# VPAC0_COMMON_0_IVPAC_TOP_0_CFG_SLV_HTS_S_VBUSP register map
Vendor: Texas Instruments
Registers are 32-bit, read-write, reset 0x0 unless marked. A register's access mark holds for its fields unless they carry their own. Offsets are as the file gives them; [hi:lo] are bit positions; {n}, {i} and the like mark numbered series; 'fields as' and 'values as' point back to an identical list.

## VPAC0_COMMON_0_IVPAC_TOP_0_CFG_SLV_HTS_S_VBUSP (part 2 of 4)
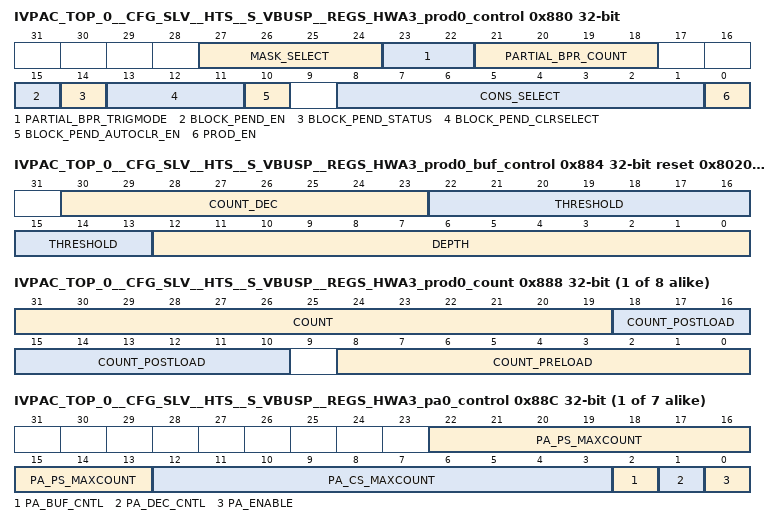
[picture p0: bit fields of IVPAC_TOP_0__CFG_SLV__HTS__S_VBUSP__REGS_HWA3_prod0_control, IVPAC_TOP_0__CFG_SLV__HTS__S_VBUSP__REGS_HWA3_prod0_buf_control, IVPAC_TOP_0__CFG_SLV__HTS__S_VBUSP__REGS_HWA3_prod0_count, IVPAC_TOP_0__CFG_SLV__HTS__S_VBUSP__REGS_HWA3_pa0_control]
0x880 IVPAC_TOP_0__CFG_SLV__HTS__S_VBUSP__REGS_HWA3_prod0_control — Controlling producer socket0 for HWA3
  [27:24] MASK_SELECT — define which tdone_mask apply to prod socket 0. tdone_mask[mask_select] applies to prod_socket0. Valid value in range 0 - 4
  [23:22] PARTIAL_BPR_TRIGMODE — 0: Normal behavior; 1 : Prod Socket 0 is used to trigger DMA channel to transfer end of Row or End of Region Row buffer data for prod socket (0+2)%4. Useful when this Buffer is not completely filled at end of row and it enables triggering separate DMA channel for end of row. Rely on tdone_bpr_early attribute; 2: Prod Socket 0 is used to trigger DMA channel to transfer end of Row or End of Region Row buffer data for prod socket (0+2)%4. Useful when this Buffer is not completely filled at end of row and it enables triggering separate DMA channel for end of row. Rely on end of Row attribute. Must not be used in dual output mode
  [21:18] PARTIAL_BPR_COUNT — Remaining block count to complete configured BPR at End of Row or End of Region Row when LDC is configured in tdone_gen_mode='0'
  [15] BLOCK_PEND_EN — '1' -> block pend at the end of hwa eop enabled at Producer socket 0 , '0' Disable
  [14] BLOCK_PEND_STATUS — '1' -> block pend status at Producer socket 0 , '0' Disable
  [13:11] BLOCK_PEND_CLRSELECT — hts_event_gen[block_pend_clrselect] will be used to clear blocked pend in super pipeline
  [10] BLOCK_PEND_AUTOCLR_EN — '1' -> Enable clearing block pend status at Producer socket 0 by hts_event_gen[block_pend_clrselect], '0' Disable
  [8:1] CONS_SELECT — consumer select for HWA3 prod socket 0. Used in decrementing count of producer buffer
  [0] PROD_EN — '1' -> Producer socket 0 enable , '0' Disable
{0x884+0x20*i} IVPAC_TOP_0__CFG_SLV__HTS__S_VBUSP__REGS_HWA3_prod{i}_buf_control reset 0x802000 (i=0..7) — Controlling producer socket{i} buffer for HWA3
  [30:23] COUNT_DEC — Count decrement value for prod count
  [22:13] THRESHOLD — Count threshold to generate pend for consumer
  [12:0] DEPTH — Maximum number of producer buffer count
{0x888+0x20*i} IVPAC_TOP_0__CFG_SLV__HTS__S_VBUSP__REGS_HWA3_prod{i}_count access per field (i=0..7) — Defining count values for pre/post load for generating pend by HWA3 prod{i}
  [31:19] COUNT ro — current count value
  [18:10] COUNT_POSTLOAD rw — count postload after producer max thread count reached
  [8:0] COUNT_PRELOAD rw — count preload after scheduler start/init
{0x88C+0x20*i} IVPAC_TOP_0__CFG_SLV__HTS__S_VBUSP__REGS_HWA3_pa{i}_control (i=0..6) — control register to manage pattern adapter on HWA3 prod socket{i}
  [22:13] PA_PS_MAXCOUNT — destination count for pattern adaptation (N), M --> N
  [12:3] PA_CS_MAXCOUNT — source count for pattern adaptation (M), M --> N
  [2] PA_BUF_CNTL — '1' -> Apply threshold, count_preload and count_postload on pattern adapter count (use this only when pa_enable='1') '0' -> Apply threshold, count_preload and count_postload on prod count (same behavior as if no pattern adapter. Note when pa_enable='1' and pa_buf_cntl='0' threshold is not used and ignored)
  [1] PA_DEC_CNTL — '1' -> post pattern adaptation, decrement ps count by count_dec , '0' -> post pattern adaptation, decrement ps count by pa_cs_maxcount
  [0] PA_ENABLE — '1' -> pa enable, '0' -> disable
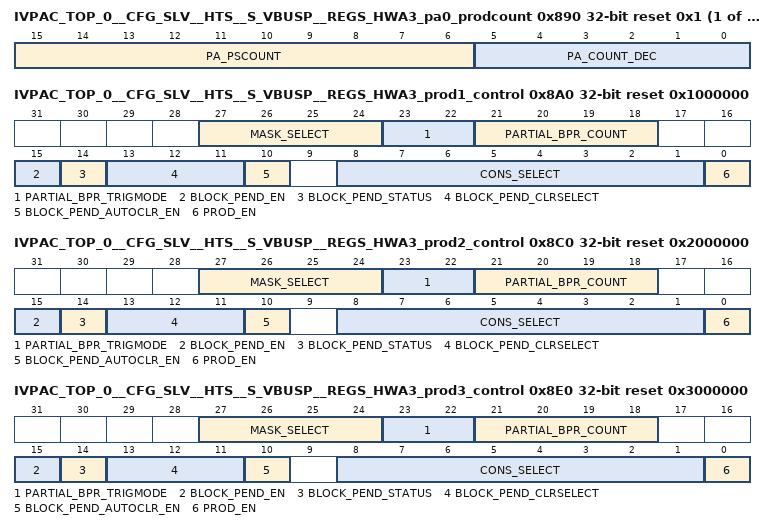
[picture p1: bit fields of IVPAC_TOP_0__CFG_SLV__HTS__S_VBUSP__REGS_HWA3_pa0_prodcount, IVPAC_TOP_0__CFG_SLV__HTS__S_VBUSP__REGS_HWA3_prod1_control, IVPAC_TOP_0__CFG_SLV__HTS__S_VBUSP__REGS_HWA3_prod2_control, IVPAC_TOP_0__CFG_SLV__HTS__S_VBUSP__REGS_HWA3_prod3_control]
{0x890+0x20*i} IVPAC_TOP_0__CFG_SLV__HTS__S_VBUSP__REGS_HWA3_pa{i}_prodcount access per field reset 0x1 (i=0..6) — count values for HWA3 prod socket{i}
  [15:6] PA_PSCOUNT ro — current count value of pa prod count
  [5:0] PA_COUNT_DEC rw — Decrement count value of pa_prod_count after pattern adapter prod count reaches threshold
0x8A0 IVPAC_TOP_0__CFG_SLV__HTS__S_VBUSP__REGS_HWA3_prod1_control reset 0x1000000 — Controlling producer socket1 for HWA3
  [27:24] MASK_SELECT — define which tdone_mask apply to prod socket 1. tdone_mask[mask_select] applies to prod_socket1. Valid value in range 0 - 4
  [23:22] PARTIAL_BPR_TRIGMODE — 0: Normal behavior; 1 : Prod Socket 1 is used to trigger DMA channel to transfer end of Row or End of Region Row buffer data for prod socket (1+2)%4. Useful when this Buffer is not completely filled at end of row and it enables triggering separate DMA channel for end of row. Rely on tdone_bpr_early attribute; 2: Prod Socket 1 is used to trigger DMA channel to transfer end of Row or End of Region Row buffer data for prod socket (1+2)%4. Useful when this Buffer is not completely filled at end of row and it enables triggering separate DMA channel for end of row. Rely on end of Row attribute. Must not be used in dual output mode
  [21:18] PARTIAL_BPR_COUNT — Remaining block count to complete configured BPR at End of Row or End of Region Row when LDC is configured in tdone_gen_mode='0'
  [15] BLOCK_PEND_EN — '1' -> block pend at the end of hwa eop enabled at Producer socket 1 , '0' Disable
  [14] BLOCK_PEND_STATUS — '1' -> block pend status at Producer socket 1 , '0' Disable
  [13:11] BLOCK_PEND_CLRSELECT — hts_event_gen[block_pend_clrselect] will be used to clear blocked pend in super pipeline
  [10] BLOCK_PEND_AUTOCLR_EN — '1' -> Enable clearing block pend status at Producer socket 1 by hts_event_gen[block_pend_clrselect], '0' Disable
  [8:1] CONS_SELECT — consumer select for HWA3 prod socket 1. Used in decrementing count of producer buffer
  [0] PROD_EN — '1' -> Producer socket 1 enable , '0' Disable
0x8C0 IVPAC_TOP_0__CFG_SLV__HTS__S_VBUSP__REGS_HWA3_prod2_control reset 0x2000000 — Controlling producer socket2 for HWA3
  [27:24] MASK_SELECT — define which tdone_mask apply to prod socket 2. tdone_mask[mask_select] applies to prod_socket2. Valid value in range 0 - 4
  [23:22] PARTIAL_BPR_TRIGMODE — 0: Normal behavior; 1 : Prod Socket 2 is used to trigger DMA channel to transfer end of Row or End of Region Row buffer data for prod socket (2+2)%4. Useful when this Buffer is not completely filled at end of row and it enables triggering separate DMA channel for end of row. Rely on tdone_bpr_early attribute; 2: Prod Socket 2 is used to trigger DMA channel to transfer end of Row or End of Region Row buffer data for prod socket (2+2)%4. Useful when this Buffer is not completely filled at end of row and it enables triggering separate DMA channel for end of row. Rely on end of Row attribute. Must not be used in dual output mode
  [21:18] PARTIAL_BPR_COUNT — Remaining block count to complete configured BPR at End of Row or End of Region Row when LDC is configured in tdone_gen_mode='0'
  [15] BLOCK_PEND_EN — '1' -> block pend at the end of hwa eop enabled at Producer socket 2 , '0' Disable
  [14] BLOCK_PEND_STATUS — '1' -> block pend status at Producer socket 2 , '0' Disable
  [13:11] BLOCK_PEND_CLRSELECT — hts_event_gen[block_pend_clrselect] will be used to clear blocked pend in super pipeline
  [10] BLOCK_PEND_AUTOCLR_EN — '1' -> Enable clearing block pend status at Producer socket 2 by hts_event_gen[block_pend_clrselect], '0' Disable
  [8:1] CONS_SELECT — consumer select for HWA3 prod socket 2. Used in decrementing count of producer buffer
  [0] PROD_EN — '1' -> Producer socket 2 enable , '0' Disable
0x8E0 IVPAC_TOP_0__CFG_SLV__HTS__S_VBUSP__REGS_HWA3_prod3_control reset 0x3000000 — Controlling producer socket3 for HWA3
  [27:24] MASK_SELECT — define which tdone_mask apply to prod socket 3. tdone_mask[mask_select] applies to prod_socket3. Valid value in range 0 - 4
  [23:22] PARTIAL_BPR_TRIGMODE — 0: Normal behavior; 1 : Prod Socket 3 is used to trigger DMA channel to transfer end of Row or End of Region Row buffer data for prod socket (3+2)%4. Useful when this Buffer is not completely filled at end of row and it enables triggering separate DMA channel for end of row. Rely on tdone_bpr_early attribute; 2: Prod Socket 3 is used to trigger DMA channel to transfer end of Row or End of Region Row buffer data for prod socket (3+2)%4. Useful when this Buffer is not completely filled at end of row and it enables triggering separate DMA channel for end of row. Rely on end of Row attribute. Must not be used in dual output mode
  [21:18] PARTIAL_BPR_COUNT — Remaining block count to complete configured BPR at End of Row or End of Region Row when LDC is configured in tdone_gen_mode='0'
  [15] BLOCK_PEND_EN — '1' -> block pend at the end of hwa eop enabled at Producer socket 3 , '0' Disable
  [14] BLOCK_PEND_STATUS — '1' -> block pend status at Producer socket 3 , '0' Disable
  [13:11] BLOCK_PEND_CLRSELECT — hts_event_gen[block_pend_clrselect] will be used to clear blocked pend in super pipeline
  [10] BLOCK_PEND_AUTOCLR_EN — '1' -> Enable clearing block pend status at Producer socket 3 by hts_event_gen[block_pend_clrselect], '0' Disable
  [8:1] CONS_SELECT — consumer select for HWA3 prod socket 3. Used in decrementing count of producer buffer
  [0] PROD_EN — '1' -> Producer socket 3 enable , '0' Disable
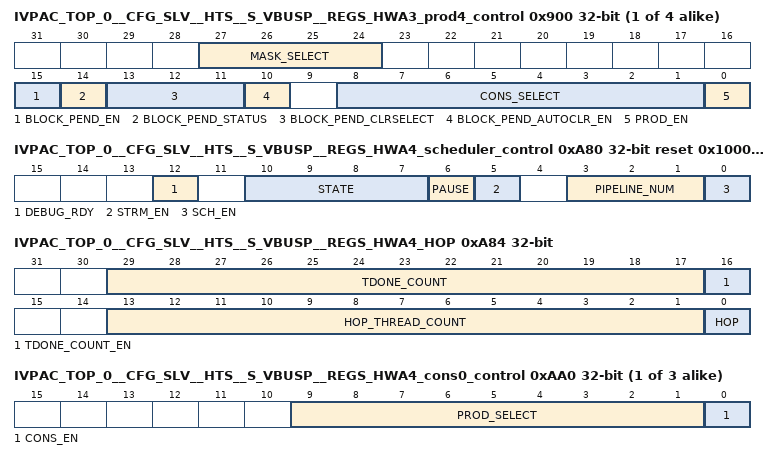
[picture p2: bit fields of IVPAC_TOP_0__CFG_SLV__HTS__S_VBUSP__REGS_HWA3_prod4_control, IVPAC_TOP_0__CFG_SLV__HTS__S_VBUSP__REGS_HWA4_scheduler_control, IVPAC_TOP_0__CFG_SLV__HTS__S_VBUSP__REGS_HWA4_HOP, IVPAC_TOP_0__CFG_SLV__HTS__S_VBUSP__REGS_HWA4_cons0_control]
{0x880+0x20*i} IVPAC_TOP_0__CFG_SLV__HTS__S_VBUSP__REGS_HWA3_prod{i}_control (i=4..7) — Controlling producer socket{i} for HWA3
  [27:24] MASK_SELECT — define which tdone_mask apply to prod socket {i}. tdone_mask[mask_select] applies to prod_socket{i}. Valid value in range 0 - 4
  [15] BLOCK_PEND_EN — '1' -> block pend at the end of hwa eop enabled at Producer socket {i} , '0' Disable
  [14] BLOCK_PEND_STATUS — '1' -> block pend status at Producer socket {i} , '0' Disable
  [13:11] BLOCK_PEND_CLRSELECT — hts_event_gen[block_pend_clrselect] will be used to clear blocked pend in super pipeline
  [10] BLOCK_PEND_AUTOCLR_EN — '1' -> Enable clearing block pend status at Producer socket {i} by hts_event_gen[block_pend_clrselect], '0' Disable
  [8:1] CONS_SELECT — consumer select for HWA3 prod socket {i}. Used in decrementing count of producer buffer
  [0] PROD_EN — '1' -> Producer socket {i} enable , '0' Disable
{0x100+0x260*i} IVPAC_TOP_0__CFG_SLV__HTS__S_VBUSP__REGS_HWA{i}_scheduler_control access per field reset 0x1000 (i=4..8) — Scheduler Control Register
  [12] DEBUG_RDY rw — '0' -> HWA{i} Scheduler resources must not be read during halted state. '1'-> HWA{i} Scheduler resources are readable during halted state
  [10:7] STATE ro — Current state of HWA{i} Scheduler
  [6] PAUSE rw — '1' -> pause/suspend scheduler , '0' -> resume scheduler
  [5] STRM_EN rw — '1' -> Streaming input enable, '0' No streaming input
  [3:1] PIPELINE_NUM rw — Pipeline Number of HWA{i} Scheduler
  [0] SCH_EN rw — scheduler enable; write '1' to enable scheduler
0xA84 IVPAC_TOP_0__CFG_SLV__HTS__S_VBUSP__REGS_HWA4_HOP access per field — Scheduler HOP Control Register. Help in detecting eop within scheduler. Once configured, it counts task/channel starts and stops issuing further starts. Specifically useful for Head of pipe dma scheduler .
  [29:17] TDONE_COUNT ro — current tdone count value
  [16] TDONE_COUNT_EN rw — '1' -> Count tdone(Not impacted due to individual channel mask). Current tdone count available as read value. when enabled, it triggers tdone_intr when (tdone_count==hop_thread_count) , '0' -> No count
  [13:1] HOP_THREAD_COUNT rw — Number of Task count for Head of pipe
  [0] HOP rw — '1' -> Head of Pipe producer Sch , '0' -> No hop
{0xAA0+8i} IVPAC_TOP_0__CFG_SLV__HTS__S_VBUSP__REGS_HWA4_cons{i}_control (i=0..2) — Controlling consumer socket {i} for HWA4
  [9:1] PROD_SELECT — producer select for HWA4 cons socket {i}
  [0] CONS_EN — '1' -> Consumer socket {i} enable , '0' Disable
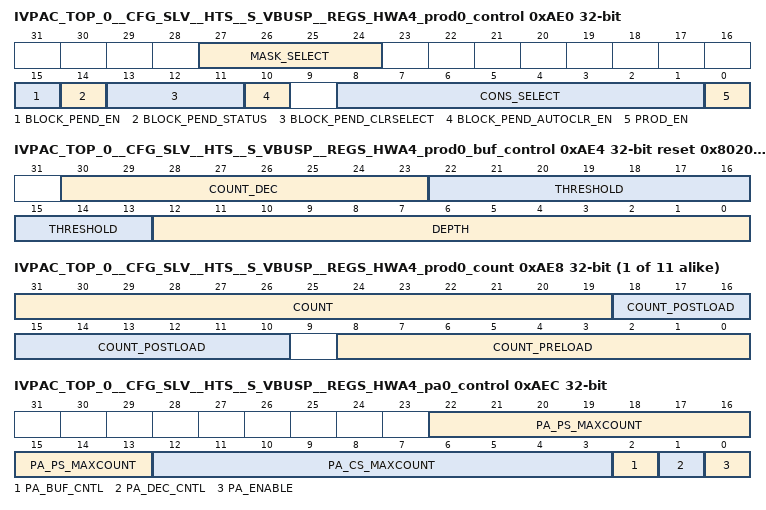
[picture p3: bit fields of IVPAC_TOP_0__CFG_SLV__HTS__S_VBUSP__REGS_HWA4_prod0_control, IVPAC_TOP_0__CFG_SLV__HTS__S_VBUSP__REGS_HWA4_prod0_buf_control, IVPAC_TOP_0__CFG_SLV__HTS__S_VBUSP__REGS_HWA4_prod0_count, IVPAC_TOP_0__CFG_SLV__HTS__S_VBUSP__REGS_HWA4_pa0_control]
0xAE0 IVPAC_TOP_0__CFG_SLV__HTS__S_VBUSP__REGS_HWA4_prod0_control — Controlling producer socket0 for HWA4
  [27:24] MASK_SELECT — define which tdone_mask apply to prod socket 0. tdone_mask[mask_select] applies to prod_socket0. Valid value in range 0 - 10
  [15] BLOCK_PEND_EN — '1' -> block pend at the end of hwa eop enabled at Producer socket 0 , '0' Disable
  [14] BLOCK_PEND_STATUS — '1' -> block pend status at Producer socket 0 , '0' Disable
  [13:11] BLOCK_PEND_CLRSELECT — hts_event_gen[block_pend_clrselect] will be used to clear blocked pend in super pipeline
  [10] BLOCK_PEND_AUTOCLR_EN — '1' -> Enable clearing block pend status at Producer socket 0 by hts_event_gen[block_pend_clrselect], '0' Disable
  [8:1] CONS_SELECT — consumer select for HWA4 prod socket 0. Used in decrementing count of producer buffer
  [0] PROD_EN — '1' -> Producer socket 0 enable , '0' Disable
{0xAE4+0x20*i} IVPAC_TOP_0__CFG_SLV__HTS__S_VBUSP__REGS_HWA4_prod{i}_buf_control reset 0x802000 (i=0..10) — Controlling producer socket{i} buffer for HWA4
  fields as IVPAC_TOP_0__CFG_SLV__HTS__S_VBUSP__REGS_HWA3_prod0_buf_control
{0xAE8+0x20*i} IVPAC_TOP_0__CFG_SLV__HTS__S_VBUSP__REGS_HWA4_prod{i}_count access per field (i=0..10) — Defining count values for pre/post load for generating pend by HWA4 prod{i}
  fields as IVPAC_TOP_0__CFG_SLV__HTS__S_VBUSP__REGS_HWA3_prod0_count
0xAEC IVPAC_TOP_0__CFG_SLV__HTS__S_VBUSP__REGS_HWA4_pa0_control — control register to manage pattern adapter on HWA4 prod socket0
  fields as IVPAC_TOP_0__CFG_SLV__HTS__S_VBUSP__REGS_HWA3_pa0_control
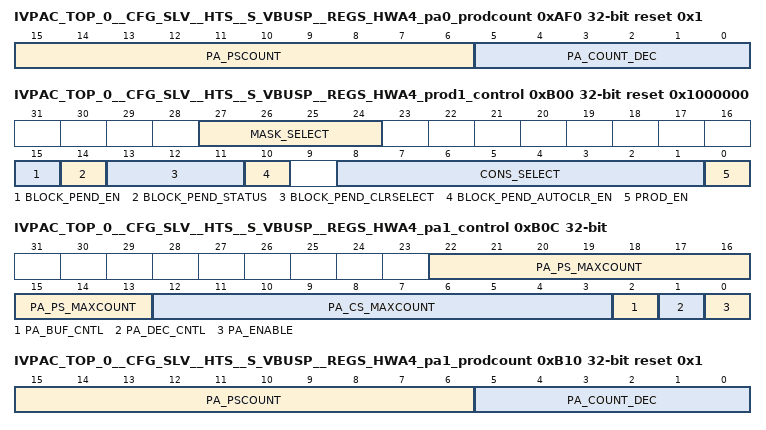
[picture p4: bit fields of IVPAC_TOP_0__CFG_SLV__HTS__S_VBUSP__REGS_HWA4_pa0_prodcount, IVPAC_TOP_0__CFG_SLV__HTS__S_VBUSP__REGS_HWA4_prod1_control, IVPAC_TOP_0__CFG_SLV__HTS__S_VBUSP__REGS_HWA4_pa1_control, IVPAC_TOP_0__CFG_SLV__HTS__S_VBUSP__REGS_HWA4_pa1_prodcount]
0xAF0 IVPAC_TOP_0__CFG_SLV__HTS__S_VBUSP__REGS_HWA4_pa0_prodcount access per field reset 0x1 — count values for HWA4 prod socket0
  fields as IVPAC_TOP_0__CFG_SLV__HTS__S_VBUSP__REGS_HWA3_pa0_prodcount
0xB00 IVPAC_TOP_0__CFG_SLV__HTS__S_VBUSP__REGS_HWA4_prod1_control reset 0x1000000 — Controlling producer socket1 for HWA4
  [27:24] MASK_SELECT — define which tdone_mask apply to prod socket 1. tdone_mask[mask_select] applies to prod_socket1. Valid value in range 0 - 10
  [15] BLOCK_PEND_EN — '1' -> block pend at the end of hwa eop enabled at Producer socket 1 , '0' Disable
  [14] BLOCK_PEND_STATUS — '1' -> block pend status at Producer socket 1 , '0' Disable
  [13:11] BLOCK_PEND_CLRSELECT — hts_event_gen[block_pend_clrselect] will be used to clear blocked pend in super pipeline
  [10] BLOCK_PEND_AUTOCLR_EN — '1' -> Enable clearing block pend status at Producer socket 1 by hts_event_gen[block_pend_clrselect], '0' Disable
  [8:1] CONS_SELECT — consumer select for HWA4 prod socket 1. Used in decrementing count of producer buffer
  [0] PROD_EN — '1' -> Producer socket 1 enable , '0' Disable
0xB0C IVPAC_TOP_0__CFG_SLV__HTS__S_VBUSP__REGS_HWA4_pa1_control — control register to manage pattern adapter on HWA4 prod socket1
  fields as IVPAC_TOP_0__CFG_SLV__HTS__S_VBUSP__REGS_HWA3_pa0_control
0xB10 IVPAC_TOP_0__CFG_SLV__HTS__S_VBUSP__REGS_HWA4_pa1_prodcount access per field reset 0x1 — count values for HWA4 prod socket1
  fields as IVPAC_TOP_0__CFG_SLV__HTS__S_VBUSP__REGS_HWA3_pa0_prodcount
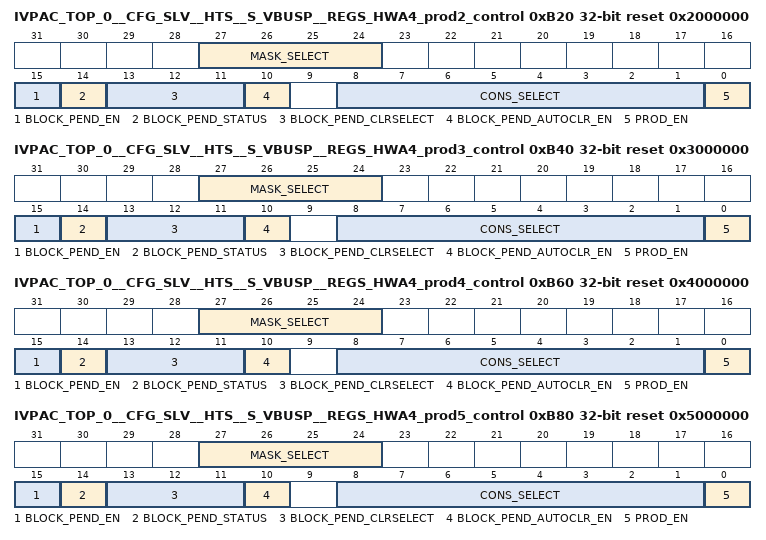
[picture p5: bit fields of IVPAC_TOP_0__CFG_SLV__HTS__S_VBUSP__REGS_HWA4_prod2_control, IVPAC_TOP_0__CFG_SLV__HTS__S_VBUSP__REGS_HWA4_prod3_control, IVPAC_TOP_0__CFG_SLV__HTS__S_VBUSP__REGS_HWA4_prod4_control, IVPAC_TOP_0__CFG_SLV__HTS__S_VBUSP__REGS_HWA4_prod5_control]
0xB20 IVPAC_TOP_0__CFG_SLV__HTS__S_VBUSP__REGS_HWA4_prod2_control reset 0x2000000 — Controlling producer socket2 for HWA4
  [27:24] MASK_SELECT — define which tdone_mask apply to prod socket 2. tdone_mask[mask_select] applies to prod_socket2. Valid value in range 0 - 10
  [15] BLOCK_PEND_EN — '1' -> block pend at the end of hwa eop enabled at Producer socket 2 , '0' Disable
  [14] BLOCK_PEND_STATUS — '1' -> block pend status at Producer socket 2 , '0' Disable
  [13:11] BLOCK_PEND_CLRSELECT — hts_event_gen[block_pend_clrselect] will be used to clear blocked pend in super pipeline
  [10] BLOCK_PEND_AUTOCLR_EN — '1' -> Enable clearing block pend status at Producer socket 2 by hts_event_gen[block_pend_clrselect], '0' Disable
  [8:1] CONS_SELECT — consumer select for HWA4 prod socket 2. Used in decrementing count of producer buffer
  [0] PROD_EN — '1' -> Producer socket 2 enable , '0' Disable
0xB40 IVPAC_TOP_0__CFG_SLV__HTS__S_VBUSP__REGS_HWA4_prod3_control reset 0x3000000 — Controlling producer socket3 for HWA4
  [27:24] MASK_SELECT — define which tdone_mask apply to prod socket 3. tdone_mask[mask_select] applies to prod_socket3. Valid value in range 0 - 10
  [15] BLOCK_PEND_EN — '1' -> block pend at the end of hwa eop enabled at Producer socket 3 , '0' Disable
  [14] BLOCK_PEND_STATUS — '1' -> block pend status at Producer socket 3 , '0' Disable
  [13:11] BLOCK_PEND_CLRSELECT — hts_event_gen[block_pend_clrselect] will be used to clear blocked pend in super pipeline
  [10] BLOCK_PEND_AUTOCLR_EN — '1' -> Enable clearing block pend status at Producer socket 3 by hts_event_gen[block_pend_clrselect], '0' Disable
  [8:1] CONS_SELECT — consumer select for HWA4 prod socket 3. Used in decrementing count of producer buffer
  [0] PROD_EN — '1' -> Producer socket 3 enable , '0' Disable
0xB60 IVPAC_TOP_0__CFG_SLV__HTS__S_VBUSP__REGS_HWA4_prod4_control reset 0x4000000 — Controlling producer socket4 for HWA4
  [27:24] MASK_SELECT — define which tdone_mask apply to prod socket 4. tdone_mask[mask_select] applies to prod_socket4. Valid value in range 0 - 10
  [15] BLOCK_PEND_EN — '1' -> block pend at the end of hwa eop enabled at Producer socket 4 , '0' Disable
  [14] BLOCK_PEND_STATUS — '1' -> block pend status at Producer socket 4 , '0' Disable
  [13:11] BLOCK_PEND_CLRSELECT — hts_event_gen[block_pend_clrselect] will be used to clear blocked pend in super pipeline
  [10] BLOCK_PEND_AUTOCLR_EN — '1' -> Enable clearing block pend status at Producer socket 4 by hts_event_gen[block_pend_clrselect], '0' Disable
  [8:1] CONS_SELECT — consumer select for HWA4 prod socket 4. Used in decrementing count of producer buffer
  [0] PROD_EN — '1' -> Producer socket 4 enable , '0' Disable
0xB80 IVPAC_TOP_0__CFG_SLV__HTS__S_VBUSP__REGS_HWA4_prod5_control reset 0x5000000 — Controlling producer socket5 for HWA4
  [27:24] MASK_SELECT — define which tdone_mask apply to prod socket 5. tdone_mask[mask_select] applies to prod_socket5. Valid value in range 0 - 10
  [15] BLOCK_PEND_EN — '1' -> block pend at the end of hwa eop enabled at Producer socket 5 , '0' Disable
  [14] BLOCK_PEND_STATUS — '1' -> block pend status at Producer socket 5 , '0' Disable
  [13:11] BLOCK_PEND_CLRSELECT — hts_event_gen[block_pend_clrselect] will be used to clear blocked pend in super pipeline
  [10] BLOCK_PEND_AUTOCLR_EN — '1' -> Enable clearing block pend status at Producer socket 5 by hts_event_gen[block_pend_clrselect], '0' Disable
  [8:1] CONS_SELECT — consumer select for HWA4 prod socket 5. Used in decrementing count of producer buffer
  [0] PROD_EN — '1' -> Producer socket 5 enable , '0' Disable
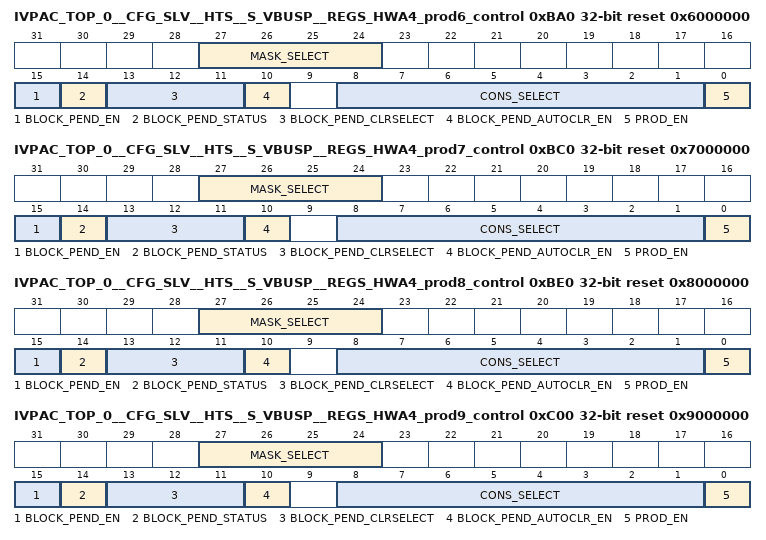
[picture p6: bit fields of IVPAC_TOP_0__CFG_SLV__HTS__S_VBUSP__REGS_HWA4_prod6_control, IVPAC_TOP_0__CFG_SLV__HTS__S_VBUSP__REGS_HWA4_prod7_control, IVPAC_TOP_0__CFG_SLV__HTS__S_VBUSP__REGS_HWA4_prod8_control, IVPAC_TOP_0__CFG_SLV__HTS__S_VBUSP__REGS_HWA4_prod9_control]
0xBA0 IVPAC_TOP_0__CFG_SLV__HTS__S_VBUSP__REGS_HWA4_prod6_control reset 0x6000000 — Controlling producer socket6 for HWA4
  [27:24] MASK_SELECT — define which tdone_mask apply to prod socket 6. tdone_mask[mask_select] applies to prod_socket6. Valid value in range 0 - 10
  [15] BLOCK_PEND_EN — '1' -> block pend at the end of hwa eop enabled at Producer socket 6 , '0' Disable
  [14] BLOCK_PEND_STATUS — '1' -> block pend status at Producer socket 6 , '0' Disable
  [13:11] BLOCK_PEND_CLRSELECT — hts_event_gen[block_pend_clrselect] will be used to clear blocked pend in super pipeline
  [10] BLOCK_PEND_AUTOCLR_EN — '1' -> Enable clearing block pend status at Producer socket 6 by hts_event_gen[block_pend_clrselect], '0' Disable
  [8:1] CONS_SELECT — consumer select for HWA4 prod socket 6. Used in decrementing count of producer buffer
  [0] PROD_EN — '1' -> Producer socket 6 enable , '0' Disable
0xBC0 IVPAC_TOP_0__CFG_SLV__HTS__S_VBUSP__REGS_HWA4_prod7_control reset 0x7000000 — Controlling producer socket7 for HWA4
  [27:24] MASK_SELECT — define which tdone_mask apply to prod socket 7. tdone_mask[mask_select] applies to prod_socket7. Valid value in range 0 - 10
  [15] BLOCK_PEND_EN — '1' -> block pend at the end of hwa eop enabled at Producer socket 7 , '0' Disable
  [14] BLOCK_PEND_STATUS — '1' -> block pend status at Producer socket 7 , '0' Disable
  [13:11] BLOCK_PEND_CLRSELECT — hts_event_gen[block_pend_clrselect] will be used to clear blocked pend in super pipeline
  [10] BLOCK_PEND_AUTOCLR_EN — '1' -> Enable clearing block pend status at Producer socket 7 by hts_event_gen[block_pend_clrselect], '0' Disable
  [8:1] CONS_SELECT — consumer select for HWA4 prod socket 7. Used in decrementing count of producer buffer
  [0] PROD_EN — '1' -> Producer socket 7 enable , '0' Disable
0xBE0 IVPAC_TOP_0__CFG_SLV__HTS__S_VBUSP__REGS_HWA4_prod8_control reset 0x8000000 — Controlling producer socket8 for HWA4
  [27:24] MASK_SELECT — define which tdone_mask apply to prod socket 8. tdone_mask[mask_select] applies to prod_socket8. Valid value in range 0 - 10
  [15] BLOCK_PEND_EN — '1' -> block pend at the end of hwa eop enabled at Producer socket 8 , '0' Disable
  [14] BLOCK_PEND_STATUS — '1' -> block pend status at Producer socket 8 , '0' Disable
  [13:11] BLOCK_PEND_CLRSELECT — hts_event_gen[block_pend_clrselect] will be used to clear blocked pend in super pipeline
  [10] BLOCK_PEND_AUTOCLR_EN — '1' -> Enable clearing block pend status at Producer socket 8 by hts_event_gen[block_pend_clrselect], '0' Disable
  [8:1] CONS_SELECT — consumer select for HWA4 prod socket 8. Used in decrementing count of producer buffer
  [0] PROD_EN — '1' -> Producer socket 8 enable , '0' Disable
0xC00 IVPAC_TOP_0__CFG_SLV__HTS__S_VBUSP__REGS_HWA4_prod9_control reset 0x9000000 — Controlling producer socket9 for HWA4
  [27:24] MASK_SELECT — define which tdone_mask apply to prod socket 9. tdone_mask[mask_select] applies to prod_socket9. Valid value in range 0 - 10
  [15] BLOCK_PEND_EN — '1' -> block pend at the end of hwa eop enabled at Producer socket 9 , '0' Disable
  [14] BLOCK_PEND_STATUS — '1' -> block pend status at Producer socket 9 , '0' Disable
  [13:11] BLOCK_PEND_CLRSELECT — hts_event_gen[block_pend_clrselect] will be used to clear blocked pend in super pipeline
  [10] BLOCK_PEND_AUTOCLR_EN — '1' -> Enable clearing block pend status at Producer socket 9 by hts_event_gen[block_pend_clrselect], '0' Disable
  [8:1] CONS_SELECT — consumer select for HWA4 prod socket 9. Used in decrementing count of producer buffer
  [0] PROD_EN — '1' -> Producer socket 9 enable , '0' Disable
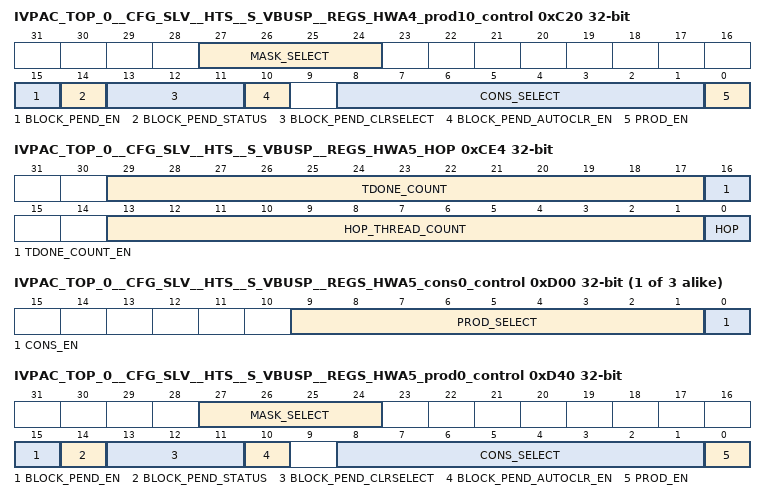
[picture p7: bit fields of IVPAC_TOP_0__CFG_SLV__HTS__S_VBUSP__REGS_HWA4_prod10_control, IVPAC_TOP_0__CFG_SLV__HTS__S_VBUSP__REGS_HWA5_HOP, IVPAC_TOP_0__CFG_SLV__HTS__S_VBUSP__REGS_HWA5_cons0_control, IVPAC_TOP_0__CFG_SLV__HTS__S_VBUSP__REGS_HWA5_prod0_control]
0xC20 IVPAC_TOP_0__CFG_SLV__HTS__S_VBUSP__REGS_HWA4_prod10_control — Controlling producer socket10 for HWA4
  [27:24] MASK_SELECT — define which tdone_mask apply to prod socket 10. tdone_mask[mask_select] applies to prod_socket10. Valid value in range 0 - 10
  [15] BLOCK_PEND_EN — '1' -> block pend at the end of hwa eop enabled at Producer socket 10 , '0' Disable
  [14] BLOCK_PEND_STATUS — '1' -> block pend status at Producer socket 10 , '0' Disable
  [13:11] BLOCK_PEND_CLRSELECT — hts_event_gen[block_pend_clrselect] will be used to clear blocked pend in super pipeline
  [10] BLOCK_PEND_AUTOCLR_EN — '1' -> Enable clearing block pend status at Producer socket 10 by hts_event_gen[block_pend_clrselect], '0' Disable
  [8:1] CONS_SELECT — consumer select for HWA4 prod socket 10. Used in decrementing count of producer buffer
  [0] PROD_EN — '1' -> Producer socket 10 enable , '0' Disable
0xCE4 IVPAC_TOP_0__CFG_SLV__HTS__S_VBUSP__REGS_HWA5_HOP access per field — Scheduler HOP Control Register. Help in detecting eop within scheduler. Once configured, it counts task/channel starts and stops issuing further starts. Specifically useful for Head of pipe dma scheduler .
  fields as IVPAC_TOP_0__CFG_SLV__HTS__S_VBUSP__REGS_HWA4_HOP
{0xD00+8i} IVPAC_TOP_0__CFG_SLV__HTS__S_VBUSP__REGS_HWA5_cons{i}_control (i=0..2) — Controlling consumer socket {i} for HWA5
  [9:1] PROD_SELECT — producer select for HWA5 cons socket {i}
  [0] CONS_EN — '1' -> Consumer socket {i} enable , '0' Disable
0xD40 IVPAC_TOP_0__CFG_SLV__HTS__S_VBUSP__REGS_HWA5_prod0_control — Controlling producer socket0 for HWA5
  [27:24] MASK_SELECT — define which tdone_mask apply to prod socket 0. tdone_mask[mask_select] applies to prod_socket0. Valid value in range 0 - 10
  [15] BLOCK_PEND_EN — '1' -> block pend at the end of hwa eop enabled at Producer socket 0 , '0' Disable
  [14] BLOCK_PEND_STATUS — '1' -> block pend status at Producer socket 0 , '0' Disable
  [13:11] BLOCK_PEND_CLRSELECT — hts_event_gen[block_pend_clrselect] will be used to clear blocked pend in super pipeline
  [10] BLOCK_PEND_AUTOCLR_EN — '1' -> Enable clearing block pend status at Producer socket 0 by hts_event_gen[block_pend_clrselect], '0' Disable
  [8:1] CONS_SELECT — consumer select for HWA5 prod socket 0. Used in decrementing count of producer buffer
  [0] PROD_EN — '1' -> Producer socket 0 enable , '0' Disable
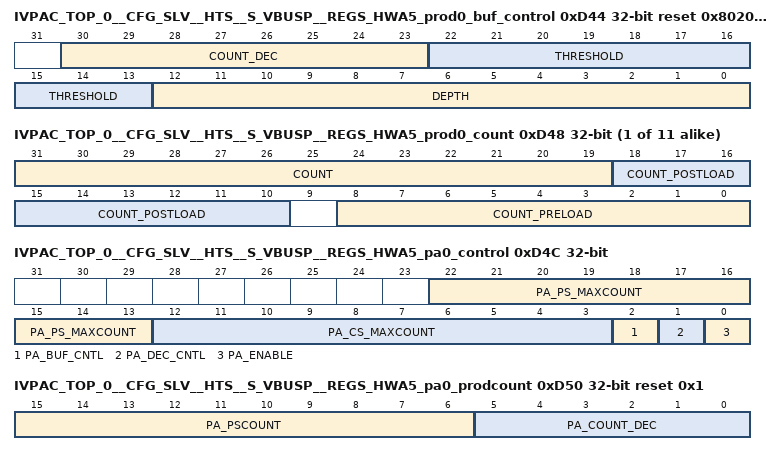
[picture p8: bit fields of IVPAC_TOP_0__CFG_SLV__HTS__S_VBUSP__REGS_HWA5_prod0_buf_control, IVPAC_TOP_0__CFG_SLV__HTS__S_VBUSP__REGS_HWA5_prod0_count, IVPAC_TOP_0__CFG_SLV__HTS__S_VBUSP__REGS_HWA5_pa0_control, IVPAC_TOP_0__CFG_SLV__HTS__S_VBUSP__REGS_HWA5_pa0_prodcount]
{0xD44+0x20*i} IVPAC_TOP_0__CFG_SLV__HTS__S_VBUSP__REGS_HWA5_prod{i}_buf_control reset 0x802000 (i=0..10) — Controlling producer socket{i} buffer for HWA5
  fields as IVPAC_TOP_0__CFG_SLV__HTS__S_VBUSP__REGS_HWA3_prod0_buf_control
{0xD48+0x20*i} IVPAC_TOP_0__CFG_SLV__HTS__S_VBUSP__REGS_HWA5_prod{i}_count access per field (i=0..10) — Defining count values for pre/post load for generating pend by HWA5 prod{i}
  fields as IVPAC_TOP_0__CFG_SLV__HTS__S_VBUSP__REGS_HWA3_prod0_count
0xD4C IVPAC_TOP_0__CFG_SLV__HTS__S_VBUSP__REGS_HWA5_pa0_control — control register to manage pattern adapter on HWA5 prod socket0
  fields as IVPAC_TOP_0__CFG_SLV__HTS__S_VBUSP__REGS_HWA3_pa0_control
0xD50 IVPAC_TOP_0__CFG_SLV__HTS__S_VBUSP__REGS_HWA5_pa0_prodcount access per field reset 0x1 — count values for HWA5 prod socket0
  fields as IVPAC_TOP_0__CFG_SLV__HTS__S_VBUSP__REGS_HWA3_pa0_prodcount
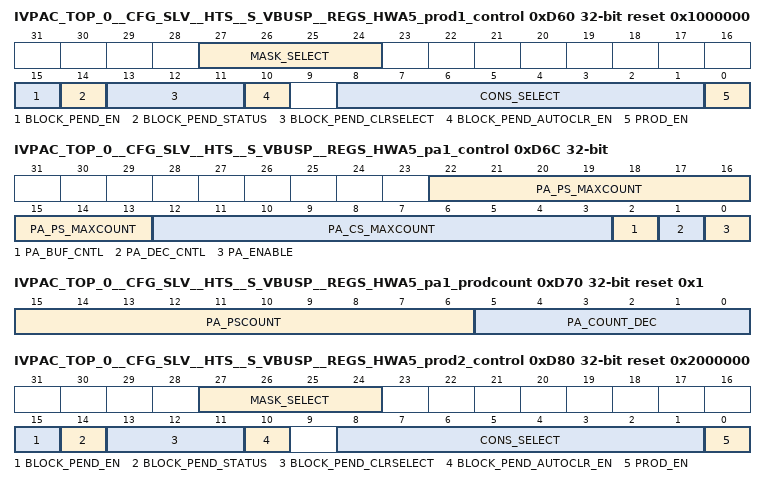
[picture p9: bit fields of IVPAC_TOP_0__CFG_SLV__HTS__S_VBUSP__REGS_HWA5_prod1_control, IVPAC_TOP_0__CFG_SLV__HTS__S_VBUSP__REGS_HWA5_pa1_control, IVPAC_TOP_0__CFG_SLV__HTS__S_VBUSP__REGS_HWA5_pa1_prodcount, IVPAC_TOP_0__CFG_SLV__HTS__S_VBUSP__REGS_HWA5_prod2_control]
0xD60 IVPAC_TOP_0__CFG_SLV__HTS__S_VBUSP__REGS_HWA5_prod1_control reset 0x1000000 — Controlling producer socket1 for HWA5
  [27:24] MASK_SELECT — define which tdone_mask apply to prod socket 1. tdone_mask[mask_select] applies to prod_socket1. Valid value in range 0 - 10
  [15] BLOCK_PEND_EN — '1' -> block pend at the end of hwa eop enabled at Producer socket 1 , '0' Disable
  [14] BLOCK_PEND_STATUS — '1' -> block pend status at Producer socket 1 , '0' Disable
  [13:11] BLOCK_PEND_CLRSELECT — hts_event_gen[block_pend_clrselect] will be used to clear blocked pend in super pipeline
  [10] BLOCK_PEND_AUTOCLR_EN — '1' -> Enable clearing block pend status at Producer socket 1 by hts_event_gen[block_pend_clrselect], '0' Disable
  [8:1] CONS_SELECT — consumer select for HWA5 prod socket 1. Used in decrementing count of producer buffer
  [0] PROD_EN — '1' -> Producer socket 1 enable , '0' Disable
0xD6C IVPAC_TOP_0__CFG_SLV__HTS__S_VBUSP__REGS_HWA5_pa1_control — control register to manage pattern adapter on HWA5 prod socket1
  fields as IVPAC_TOP_0__CFG_SLV__HTS__S_VBUSP__REGS_HWA3_pa0_control
0xD70 IVPAC_TOP_0__CFG_SLV__HTS__S_VBUSP__REGS_HWA5_pa1_prodcount access per field reset 0x1 — count values for HWA5 prod socket1
  fields as IVPAC_TOP_0__CFG_SLV__HTS__S_VBUSP__REGS_HWA3_pa0_prodcount
0xD80 IVPAC_TOP_0__CFG_SLV__HTS__S_VBUSP__REGS_HWA5_prod2_control reset 0x2000000 — Controlling producer socket2 for HWA5
  [27:24] MASK_SELECT — define which tdone_mask apply to prod socket 2. tdone_mask[mask_select] applies to prod_socket2. Valid value in range 0 - 10
  [15] BLOCK_PEND_EN — '1' -> block pend at the end of hwa eop enabled at Producer socket 2 , '0' Disable
  [14] BLOCK_PEND_STATUS — '1' -> block pend status at Producer socket 2 , '0' Disable
  [13:11] BLOCK_PEND_CLRSELECT — hts_event_gen[block_pend_clrselect] will be used to clear blocked pend in super pipeline
  [10] BLOCK_PEND_AUTOCLR_EN — '1' -> Enable clearing block pend status at Producer socket 2 by hts_event_gen[block_pend_clrselect], '0' Disable
  [8:1] CONS_SELECT — consumer select for HWA5 prod socket 2. Used in decrementing count of producer buffer
  [0] PROD_EN — '1' -> Producer socket 2 enable , '0' Disable
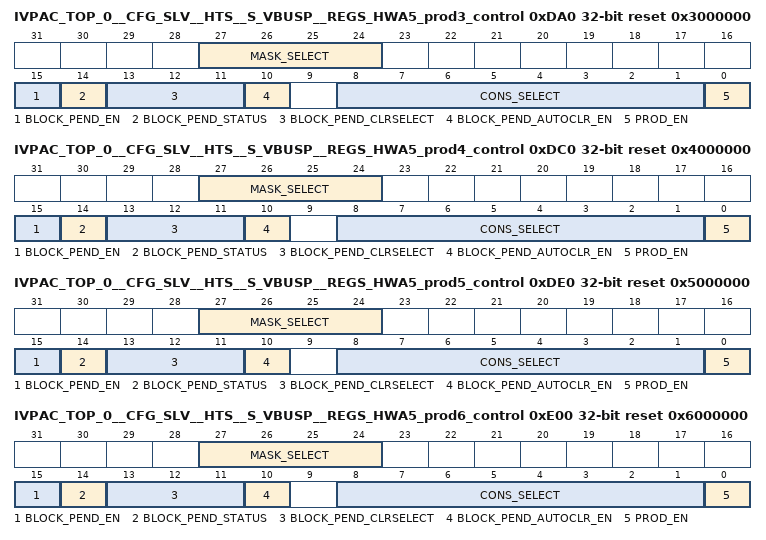
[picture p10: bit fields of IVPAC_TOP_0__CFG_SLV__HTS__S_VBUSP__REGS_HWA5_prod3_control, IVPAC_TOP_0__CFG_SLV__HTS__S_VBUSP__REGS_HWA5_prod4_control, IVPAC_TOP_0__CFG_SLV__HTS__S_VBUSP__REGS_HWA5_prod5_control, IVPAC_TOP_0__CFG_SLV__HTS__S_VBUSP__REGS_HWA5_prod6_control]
0xDA0 IVPAC_TOP_0__CFG_SLV__HTS__S_VBUSP__REGS_HWA5_prod3_control reset 0x3000000 — Controlling producer socket3 for HWA5
  [27:24] MASK_SELECT — define which tdone_mask apply to prod socket 3. tdone_mask[mask_select] applies to prod_socket3. Valid value in range 0 - 10
  [15] BLOCK_PEND_EN — '1' -> block pend at the end of hwa eop enabled at Producer socket 3 , '0' Disable
  [14] BLOCK_PEND_STATUS — '1' -> block pend status at Producer socket 3 , '0' Disable
  [13:11] BLOCK_PEND_CLRSELECT — hts_event_gen[block_pend_clrselect] will be used to clear blocked pend in super pipeline
  [10] BLOCK_PEND_AUTOCLR_EN — '1' -> Enable clearing block pend status at Producer socket 3 by hts_event_gen[block_pend_clrselect], '0' Disable
  [8:1] CONS_SELECT — consumer select for HWA5 prod socket 3. Used in decrementing count of producer buffer
  [0] PROD_EN — '1' -> Producer socket 3 enable , '0' Disable
0xDC0 IVPAC_TOP_0__CFG_SLV__HTS__S_VBUSP__REGS_HWA5_prod4_control reset 0x4000000 — Controlling producer socket4 for HWA5
  [27:24] MASK_SELECT — define which tdone_mask apply to prod socket 4. tdone_mask[mask_select] applies to prod_socket4. Valid value in range 0 - 10
  [15] BLOCK_PEND_EN — '1' -> block pend at the end of hwa eop enabled at Producer socket 4 , '0' Disable
  [14] BLOCK_PEND_STATUS — '1' -> block pend status at Producer socket 4 , '0' Disable
  [13:11] BLOCK_PEND_CLRSELECT — hts_event_gen[block_pend_clrselect] will be used to clear blocked pend in super pipeline
  [10] BLOCK_PEND_AUTOCLR_EN — '1' -> Enable clearing block pend status at Producer socket 4 by hts_event_gen[block_pend_clrselect], '0' Disable
  [8:1] CONS_SELECT — consumer select for HWA5 prod socket 4. Used in decrementing count of producer buffer
  [0] PROD_EN — '1' -> Producer socket 4 enable , '0' Disable
0xDE0 IVPAC_TOP_0__CFG_SLV__HTS__S_VBUSP__REGS_HWA5_prod5_control reset 0x5000000 — Controlling producer socket5 for HWA5
  [27:24] MASK_SELECT — define which tdone_mask apply to prod socket 5. tdone_mask[mask_select] applies to prod_socket5. Valid value in range 0 - 10
  [15] BLOCK_PEND_EN — '1' -> block pend at the end of hwa eop enabled at Producer socket 5 , '0' Disable
  [14] BLOCK_PEND_STATUS — '1' -> block pend status at Producer socket 5 , '0' Disable
  [13:11] BLOCK_PEND_CLRSELECT — hts_event_gen[block_pend_clrselect] will be used to clear blocked pend in super pipeline
  [10] BLOCK_PEND_AUTOCLR_EN — '1' -> Enable clearing block pend status at Producer socket 5 by hts_event_gen[block_pend_clrselect], '0' Disable
  [8:1] CONS_SELECT — consumer select for HWA5 prod socket 5. Used in decrementing count of producer buffer
  [0] PROD_EN — '1' -> Producer socket 5 enable , '0' Disable
0xE00 IVPAC_TOP_0__CFG_SLV__HTS__S_VBUSP__REGS_HWA5_prod6_control reset 0x6000000 — Controlling producer socket6 for HWA5
  [27:24] MASK_SELECT — define which tdone_mask apply to prod socket 6. tdone_mask[mask_select] applies to prod_socket6. Valid value in range 0 - 10
  [15] BLOCK_PEND_EN — '1' -> block pend at the end of hwa eop enabled at Producer socket 6 , '0' Disable
  [14] BLOCK_PEND_STATUS — '1' -> block pend status at Producer socket 6 , '0' Disable
  [13:11] BLOCK_PEND_CLRSELECT — hts_event_gen[block_pend_clrselect] will be used to clear blocked pend in super pipeline
  [10] BLOCK_PEND_AUTOCLR_EN — '1' -> Enable clearing block pend status at Producer socket 6 by hts_event_gen[block_pend_clrselect], '0' Disable
  [8:1] CONS_SELECT — consumer select for HWA5 prod socket 6. Used in decrementing count of producer buffer
  [0] PROD_EN — '1' -> Producer socket 6 enable , '0' Disable
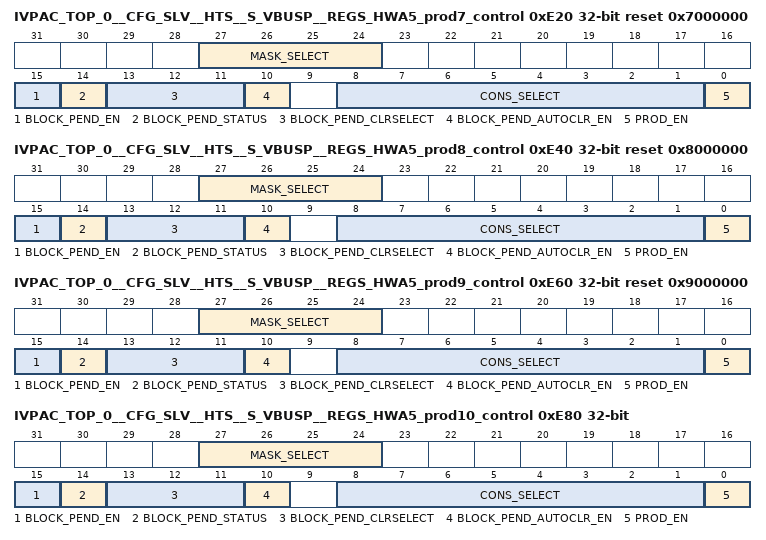
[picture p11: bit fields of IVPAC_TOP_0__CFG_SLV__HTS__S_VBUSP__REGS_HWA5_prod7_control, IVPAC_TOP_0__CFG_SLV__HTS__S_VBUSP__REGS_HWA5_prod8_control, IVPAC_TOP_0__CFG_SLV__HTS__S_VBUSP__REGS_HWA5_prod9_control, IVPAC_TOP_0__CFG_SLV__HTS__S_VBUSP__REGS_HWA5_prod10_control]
0xE20 IVPAC_TOP_0__CFG_SLV__HTS__S_VBUSP__REGS_HWA5_prod7_control reset 0x7000000 — Controlling producer socket7 for HWA5
  [27:24] MASK_SELECT — define which tdone_mask apply to prod socket 7. tdone_mask[mask_select] applies to prod_socket7. Valid value in range 0 - 10
  [15] BLOCK_PEND_EN — '1' -> block pend at the end of hwa eop enabled at Producer socket 7 , '0' Disable
  [14] BLOCK_PEND_STATUS — '1' -> block pend status at Producer socket 7 , '0' Disable
  [13:11] BLOCK_PEND_CLRSELECT — hts_event_gen[block_pend_clrselect] will be used to clear blocked pend in super pipeline
  [10] BLOCK_PEND_AUTOCLR_EN — '1' -> Enable clearing block pend status at Producer socket 7 by hts_event_gen[block_pend_clrselect], '0' Disable
  [8:1] CONS_SELECT — consumer select for HWA5 prod socket 7. Used in decrementing count of producer buffer
  [0] PROD_EN — '1' -> Producer socket 7 enable , '0' Disable
0xE40 IVPAC_TOP_0__CFG_SLV__HTS__S_VBUSP__REGS_HWA5_prod8_control reset 0x8000000 — Controlling producer socket8 for HWA5
  [27:24] MASK_SELECT — define which tdone_mask apply to prod socket 8. tdone_mask[mask_select] applies to prod_socket8. Valid value in range 0 - 10
  [15] BLOCK_PEND_EN — '1' -> block pend at the end of hwa eop enabled at Producer socket 8 , '0' Disable
  [14] BLOCK_PEND_STATUS — '1' -> block pend status at Producer socket 8 , '0' Disable
  [13:11] BLOCK_PEND_CLRSELECT — hts_event_gen[block_pend_clrselect] will be used to clear blocked pend in super pipeline
  [10] BLOCK_PEND_AUTOCLR_EN — '1' -> Enable clearing block pend status at Producer socket 8 by hts_event_gen[block_pend_clrselect], '0' Disable
  [8:1] CONS_SELECT — consumer select for HWA5 prod socket 8. Used in decrementing count of producer buffer
  [0] PROD_EN — '1' -> Producer socket 8 enable , '0' Disable
0xE60 IVPAC_TOP_0__CFG_SLV__HTS__S_VBUSP__REGS_HWA5_prod9_control reset 0x9000000 — Controlling producer socket9 for HWA5
  [27:24] MASK_SELECT — define which tdone_mask apply to prod socket 9. tdone_mask[mask_select] applies to prod_socket9. Valid value in range 0 - 10
  [15] BLOCK_PEND_EN — '1' -> block pend at the end of hwa eop enabled at Producer socket 9 , '0' Disable
  [14] BLOCK_PEND_STATUS — '1' -> block pend status at Producer socket 9 , '0' Disable
  [13:11] BLOCK_PEND_CLRSELECT — hts_event_gen[block_pend_clrselect] will be used to clear blocked pend in super pipeline
  [10] BLOCK_PEND_AUTOCLR_EN — '1' -> Enable clearing block pend status at Producer socket 9 by hts_event_gen[block_pend_clrselect], '0' Disable
  [8:1] CONS_SELECT — consumer select for HWA5 prod socket 9. Used in decrementing count of producer buffer
  [0] PROD_EN — '1' -> Producer socket 9 enable , '0' Disable
0xE80 IVPAC_TOP_0__CFG_SLV__HTS__S_VBUSP__REGS_HWA5_prod10_control — Controlling producer socket10 for HWA5
  [27:24] MASK_SELECT — define which tdone_mask apply to prod socket 10. tdone_mask[mask_select] applies to prod_socket10. Valid value in range 0 - 10
  [15] BLOCK_PEND_EN — '1' -> block pend at the end of hwa eop enabled at Producer socket 10 , '0' Disable
  [14] BLOCK_PEND_STATUS — '1' -> block pend status at Producer socket 10 , '0' Disable
  [13:11] BLOCK_PEND_CLRSELECT — hts_event_gen[block_pend_clrselect] will be used to clear blocked pend in super pipeline
  [10] BLOCK_PEND_AUTOCLR_EN — '1' -> Enable clearing block pend status at Producer socket 10 by hts_event_gen[block_pend_clrselect], '0' Disable
  [8:1] CONS_SELECT — consumer select for HWA5 prod socket 10. Used in decrementing count of producer buffer
  [0] PROD_EN — '1' -> Producer socket 10 enable , '0' Disable
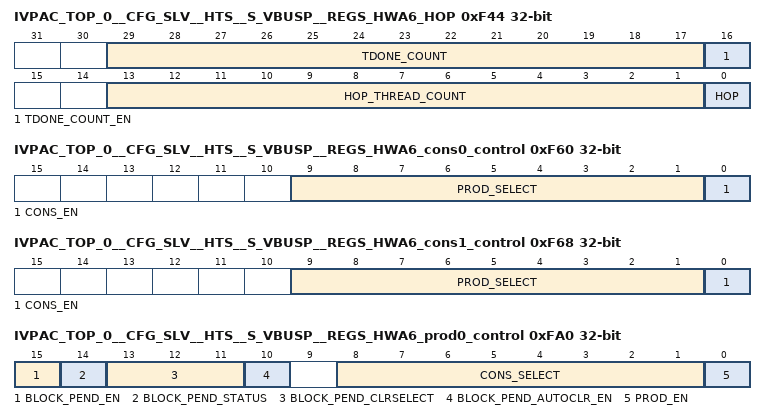
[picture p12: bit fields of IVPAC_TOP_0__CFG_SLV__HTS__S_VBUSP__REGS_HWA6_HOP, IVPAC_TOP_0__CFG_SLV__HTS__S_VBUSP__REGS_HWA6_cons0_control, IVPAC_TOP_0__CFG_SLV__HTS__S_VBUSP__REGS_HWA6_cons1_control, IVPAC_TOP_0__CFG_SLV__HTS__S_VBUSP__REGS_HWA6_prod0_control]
0xF44 IVPAC_TOP_0__CFG_SLV__HTS__S_VBUSP__REGS_HWA6_HOP access per field — Scheduler HOP Control Register. Help in detecting eop within scheduler. Once configured, it counts task/channel starts and stops issuing further starts. Specifically useful for Head of pipe dma scheduler .
  [29:17] TDONE_COUNT ro — current tdone count value
  [16] TDONE_COUNT_EN rw — '1' -> Count tdone(Not impacted due to individual channel mask). Current tdone count available as read value . when enabled, it triggers tdone_intr when (tdone_count==hop_thread_count) '0' -> No count
  [13:1] HOP_THREAD_COUNT rw — Number of Task count for Head of pipe
  [0] HOP rw — '1' -> Head of Pipe producer Sch , '0' -> No hop
0xF60 IVPAC_TOP_0__CFG_SLV__HTS__S_VBUSP__REGS_HWA6_cons0_control — Controlling consumer socket 0 for HWA6
  [9:1] PROD_SELECT — producer select for HWA6 cons socket 0
  [0] CONS_EN — '1' -> Consumer socket 0 enable , '0' Disable
0xF68 IVPAC_TOP_0__CFG_SLV__HTS__S_VBUSP__REGS_HWA6_cons1_control — Controlling consumer socket 1 for HWA6
  [9:1] PROD_SELECT — producer select for HWA6 cons socket 1
  [0] CONS_EN — '1' -> Consumer socket 1 enable , '0' Disable
0xFA0 IVPAC_TOP_0__CFG_SLV__HTS__S_VBUSP__REGS_HWA6_prod0_control — Controlling producer socket0 for HWA6
  [15] BLOCK_PEND_EN — '1' -> block pend at the end of hwa eop enabled at Producer socket 0 , '0' Disable
  [14] BLOCK_PEND_STATUS — '1' -> block pend status at Producer socket 0 , '0' Disable
  [13:11] BLOCK_PEND_CLRSELECT — hts_event_gen[block_pend_clrselect] will be used to clear blocked pend in super pipeline
  [10] BLOCK_PEND_AUTOCLR_EN — '1' -> Enable clearing block pend status at Producer socket 0 by hts_event_gen[block_pend_clrselect], '0' Disable
  [8:1] CONS_SELECT — consumer select for HWA6 prod socket 0. Used in decrementing count of producer buffer
  [0] PROD_EN — '1' -> Producer socket 0 enable , '0' Disable
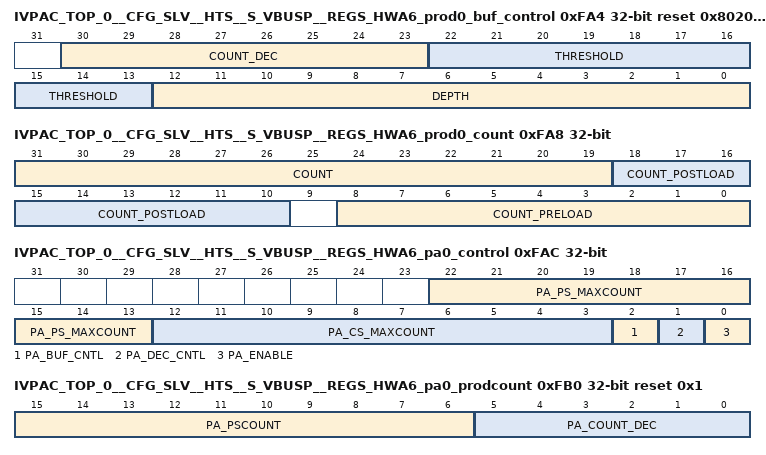
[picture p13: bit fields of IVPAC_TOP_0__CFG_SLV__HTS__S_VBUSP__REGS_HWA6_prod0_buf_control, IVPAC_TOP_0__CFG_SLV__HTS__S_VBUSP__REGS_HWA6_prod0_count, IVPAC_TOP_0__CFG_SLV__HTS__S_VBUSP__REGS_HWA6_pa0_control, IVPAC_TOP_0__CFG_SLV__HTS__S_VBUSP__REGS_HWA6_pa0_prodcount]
0xFA4 IVPAC_TOP_0__CFG_SLV__HTS__S_VBUSP__REGS_HWA6_prod0_buf_control reset 0x802000 — Controlling producer socket0 buffer for HWA6
  fields as IVPAC_TOP_0__CFG_SLV__HTS__S_VBUSP__REGS_HWA3_prod0_buf_control
0xFA8 IVPAC_TOP_0__CFG_SLV__HTS__S_VBUSP__REGS_HWA6_prod0_count access per field — Defining count values for pre/post load for generating pend by HWA6 prod0
  fields as IVPAC_TOP_0__CFG_SLV__HTS__S_VBUSP__REGS_HWA3_prod0_count
0xFAC IVPAC_TOP_0__CFG_SLV__HTS__S_VBUSP__REGS_HWA6_pa0_control — control register to manage pattern adapter on HWA6 prod socket0
  fields as IVPAC_TOP_0__CFG_SLV__HTS__S_VBUSP__REGS_HWA3_pa0_control
0xFB0 IVPAC_TOP_0__CFG_SLV__HTS__S_VBUSP__REGS_HWA6_pa0_prodcount access per field reset 0x1 — count values for HWA6 prod socket0
  fields as IVPAC_TOP_0__CFG_SLV__HTS__S_VBUSP__REGS_HWA3_pa0_prodcount
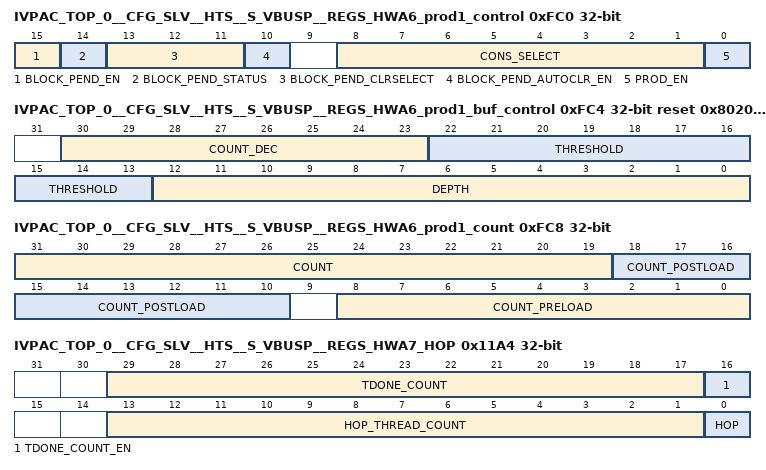
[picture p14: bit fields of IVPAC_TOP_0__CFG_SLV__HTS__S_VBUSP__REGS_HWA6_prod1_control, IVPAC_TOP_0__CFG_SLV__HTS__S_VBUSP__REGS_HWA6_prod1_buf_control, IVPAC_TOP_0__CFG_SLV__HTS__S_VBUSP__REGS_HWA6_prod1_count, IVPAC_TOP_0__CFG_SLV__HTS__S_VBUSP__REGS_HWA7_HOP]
0xFC0 IVPAC_TOP_0__CFG_SLV__HTS__S_VBUSP__REGS_HWA6_prod1_control — Controlling producer socket1 for HWA6
  [15] BLOCK_PEND_EN — '1' -> block pend at the end of hwa eop enabled at Producer socket 1 , '0' Disable
  [14] BLOCK_PEND_STATUS — '1' -> block pend status at Producer socket 1 , '0' Disable
  [13:11] BLOCK_PEND_CLRSELECT — hts_event_gen[block_pend_clrselect] will be used to clear blocked pend in super pipeline
  [10] BLOCK_PEND_AUTOCLR_EN — '1' -> Enable clearing block pend status at Producer socket 1 by hts_event_gen[block_pend_clrselect], '0' Disable
  [8:1] CONS_SELECT — consumer select for HWA6 prod socket 1. Used in decrementing count of producer buffer
  [0] PROD_EN — '1' -> Producer socket 1 enable , '0' Disable
0xFC4 IVPAC_TOP_0__CFG_SLV__HTS__S_VBUSP__REGS_HWA6_prod1_buf_control reset 0x802000 — Controlling producer socket1 buffer for HWA6
  fields as IVPAC_TOP_0__CFG_SLV__HTS__S_VBUSP__REGS_HWA3_prod0_buf_control
0xFC8 IVPAC_TOP_0__CFG_SLV__HTS__S_VBUSP__REGS_HWA6_prod1_count access per field — Defining count values for pre/post load for generating pend by HWA6 prod1
  fields as IVPAC_TOP_0__CFG_SLV__HTS__S_VBUSP__REGS_HWA3_prod0_count
0x11A4 IVPAC_TOP_0__CFG_SLV__HTS__S_VBUSP__REGS_HWA7_HOP access per field — Scheduler HOP Control Register. Help in detecting eop within scheduler. Once configured, it counts task/channel starts and stops issuing further start. Specifically useful for Head of pipe dma scheduler .
  [29:17] TDONE_COUNT ro — current tdone count value
  [16] TDONE_COUNT_EN rw — '1' -> Count tdone(Not impacted due to individual channel mask). Current tdone count available as read value . when enabled, it triggers tdone_intr when (tdone_count==hop_thread_count) , '0' -> No count
  [13:1] HOP_THREAD_COUNT rw — Number of Task count for Head of pipe
  [0] HOP rw — '1' -> Head of Pipe producer Sch , '0' -> No hop
{0x11C0+8i} IVPAC_TOP_0__CFG_SLV__HTS__S_VBUSP__REGS_HWA7_cons{i}_control (i=0..4) — Controlling consumer socket {i} for HWA7
  [9:1] PROD_SELECT — producer select for HWA7 cons socket {i}
  [0] CONS_EN — '1' -> Consumer socket {i} enable , '0' Disable
0x1200 IVPAC_TOP_0__CFG_SLV__HTS__S_VBUSP__REGS_HWA7_prod0_control — Controlling producer socket0 for HWA7
  [27:24] MASK_SELECT — define which tdone_mask apply to prod socket 0. tdone_mask[mask_select] applies to prod_socket0. Valid value in range 0 - 4
  [15] BLOCK_PEND_EN — '1' -> block pend at the end of hwa eop enabled at Producer socket 0 , '0' Disable
  [14] BLOCK_PEND_STATUS — '1' -> block pend status at Producer socket 0 , '0' Disable
  [13:11] BLOCK_PEND_CLRSELECT — hts_event_gen[block_pend_clrselect] will be used to clear blocked pend in super pipeline
  [10] BLOCK_PEND_AUTOCLR_EN — '1' -> Enable clearing block pend status at Producer socket 0 by hts_event_gen[block_pend_clrselect], '0' Disable
  [8:1] CONS_SELECT — consumer select for HWA7 prod socket 0. Used in decrementing count of producer buffer
  [0] PROD_EN — '1' -> Producer socket 0 enable , '0' Disable
{0x1204+0x20*i} IVPAC_TOP_0__CFG_SLV__HTS__S_VBUSP__REGS_HWA7_prod{i}_buf_control reset 0x802000 (i=0..4) — Controlling producer socket{i} buffer for HWA7
  fields as IVPAC_TOP_0__CFG_SLV__HTS__S_VBUSP__REGS_HWA3_prod0_buf_control
{0x1208+0x20*i} IVPAC_TOP_0__CFG_SLV__HTS__S_VBUSP__REGS_HWA7_prod{i}_count access per field (i=0..4) — Defining count values for pre/post load for generating pend by HWA7 prod{i}
  fields as IVPAC_TOP_0__CFG_SLV__HTS__S_VBUSP__REGS_HWA3_prod0_count
{0x120C+0x20*i} IVPAC_TOP_0__CFG_SLV__HTS__S_VBUSP__REGS_HWA7_pa{i}_control (i=0..3) — control register to manage pattern adapter on HWA7 prod socket{i}
  fields as IVPAC_TOP_0__CFG_SLV__HTS__S_VBUSP__REGS_HWA3_pa0_control
{0x1210+0x20*i} IVPAC_TOP_0__CFG_SLV__HTS__S_VBUSP__REGS_HWA7_pa{i}_prodcount access per field reset 0x1 (i=0..3) — count values for HWA7 prod socket{i}
  fields as IVPAC_TOP_0__CFG_SLV__HTS__S_VBUSP__REGS_HWA3_pa0_prodcount
0x1220 IVPAC_TOP_0__CFG_SLV__HTS__S_VBUSP__REGS_HWA7_prod1_control reset 0x1000000 — Controlling producer socket1 for HWA7
  [27:24] MASK_SELECT — define which tdone_mask apply to prod socket 1. tdone_mask[mask_select] applies to prod_socket1. Valid value in range 0 - 4
  [15] BLOCK_PEND_EN — '1' -> block pend at the end of hwa eop enabled at Producer socket 1 , '0' Disable
  [14] BLOCK_PEND_STATUS — '1' -> block pend status at Producer socket 1 , '0' Disable
  [13:11] BLOCK_PEND_CLRSELECT — hts_event_gen[block_pend_clrselect] will be used to clear blocked pend in super pipeline
  [10] BLOCK_PEND_AUTOCLR_EN — '1' -> Enable clearing block pend status at Producer socket 1 by hts_event_gen[block_pend_clrselect], '0' Disable
  [8:1] CONS_SELECT — consumer select for HWA7 prod socket 1. Used in decrementing count of producer buffer
  [0] PROD_EN — '1' -> Producer socket 1 enable , '0' Disable
0x1240 IVPAC_TOP_0__CFG_SLV__HTS__S_VBUSP__REGS_HWA7_prod2_control reset 0x2000000 — Controlling producer socket2 for HWA7
  [27:24] MASK_SELECT — define which tdone_mask apply to prod socket 2. tdone_mask[mask_select] applies to prod_socket2. Valid value in range 0 - 4
  [15] BLOCK_PEND_EN — '1' -> block pend at the end of hwa eop enabled at Producer socket 2 , '0' Disable
  [14] BLOCK_PEND_STATUS — '1' -> block pend status at Producer socket 2 , '0' Disable
  [13:11] BLOCK_PEND_CLRSELECT — hts_event_gen[block_pend_clrselect] will be used to clear blocked pend in super pipeline
  [10] BLOCK_PEND_AUTOCLR_EN — '1' -> Enable clearing block pend status at Producer socket 2 by hts_event_gen[block_pend_clrselect], '0' Disable
  [8:1] CONS_SELECT — consumer select for HWA7 prod socket 2. Used in decrementing count of producer buffer
  [0] PROD_EN — '1' -> Producer socket 2 enable , '0' Disable
0x1260 IVPAC_TOP_0__CFG_SLV__HTS__S_VBUSP__REGS_HWA7_prod3_control reset 0x3000000 — Controlling producer socket3 for HWA7
  [27:24] MASK_SELECT — define which tdone_mask apply to prod socket 3. tdone_mask[mask_select] applies to prod_socket3. Valid value in range 0 - 4
  [15] BLOCK_PEND_EN — '1' -> block pend at the end of hwa eop enabled at Producer socket 3 , '0' Disable
  [14] BLOCK_PEND_STATUS — '1' -> block pend status at Producer socket 3 , '0' Disable
  [13:11] BLOCK_PEND_CLRSELECT — hts_event_gen[block_pend_clrselect] will be used to clear blocked pend in super pipeline
  [10] BLOCK_PEND_AUTOCLR_EN — '1' -> Enable clearing block pend status at Producer socket 3 by hts_event_gen[block_pend_clrselect], '0' Disable
  [8:1] CONS_SELECT — consumer select for HWA7 prod socket 3. Used in decrementing count of producer buffer
  [0] PROD_EN — '1' -> Producer socket 3 enable , '0' Disable
0x1280 IVPAC_TOP_0__CFG_SLV__HTS__S_VBUSP__REGS_HWA7_prod4_control — Controlling producer socket4 for HWA7
  [27:24] MASK_SELECT — define which tdone_mask apply to prod socket 4. tdone_mask[mask_select] applies to prod_socket4. Valid value in range 0 - 4
  [15] BLOCK_PEND_EN — '1' -> block pend at the end of hwa eop enabled at Producer socket 4 , '0' Disable
  [14] BLOCK_PEND_STATUS — '1' -> block pend status at Producer socket 4 , '0' Disable
  [13:11] BLOCK_PEND_CLRSELECT — hts_event_gen[block_pend_clrselect] will be used to clear blocked pend in super pipeline
  [10] BLOCK_PEND_AUTOCLR_EN — '1' -> Enable clearing block pend status at Producer socket 4 by hts_event_gen[block_pend_clrselect], '0' Disable
  [8:1] CONS_SELECT — consumer select for HWA7 prod socket 4. Used in decrementing count of producer buffer
  [0] PROD_EN — '1' -> Producer socket 4 enable , '0' Disable
